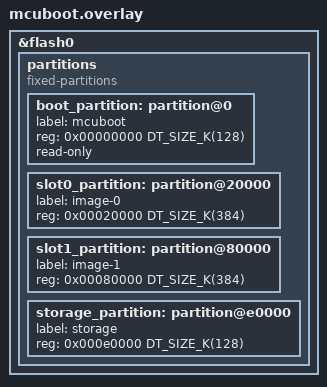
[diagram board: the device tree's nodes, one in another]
/*
 * Shared flash partition layout for MCUboot (1MB M7 flash @ 0x08000000, aligned to 128KB sectors)
 *
 * Remove ranges from flash0 to prevent DT_FIXED_PARTITION_ADDR from
 * double-adding the flash base address. See test_minimal/sysbuild/mcuboot.overlay for details.
 */
&flash0 {
    /delete-property/ ranges;

    partitions {
        compatible = "fixed-partitions";
        #address-cells = <1>;
        #size-cells = <1>;
        ranges;

        boot_partition: partition@0 {
            label = "mcuboot";
            reg = <0x00000000 DT_SIZE_K(128)>;
            read-only;
        };

        slot0_partition: partition@20000 {
            label = "image-0";
            reg = <0x00020000 DT_SIZE_K(384)>;
        };

        slot1_partition: partition@80000 {
            label = "image-1";
            reg = <0x00080000 DT_SIZE_K(384)>;
        };

        storage_partition: partition@e0000 {
            label = "storage";
            reg = <0x000e0000 DT_SIZE_K(128)>;
        };
    };
};
